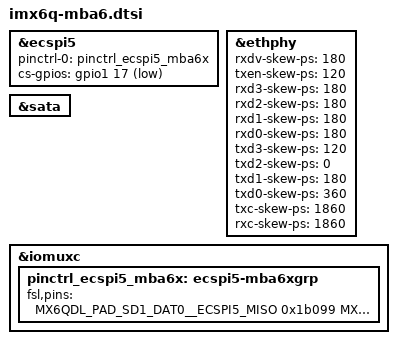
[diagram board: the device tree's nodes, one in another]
// SPDX-License-Identifier: GPL-2.0-only
/*
 * Copyright 2013 Sascha Hauer, Pengutronix
 *
 * Copyright 2013-2021 TQ-Systems GmbH
 * Author: Markus Niebel <Markus.Niebel@tq-group.com>
 */

&ecspi5 {
	pinctrl-names = "default";
	pinctrl-0 = <&pinctrl_ecspi5_mba6x>;
	cs-gpios = <&gpio1 17 GPIO_ACTIVE_LOW>;
};

&ethphy {
	rxdv-skew-ps = <180>;
	txen-skew-ps = <120>;
	rxd3-skew-ps = <180>;
	rxd2-skew-ps = <180>;
	rxd1-skew-ps = <180>;
	rxd0-skew-ps = <180>;
	txd3-skew-ps = <120>;
	txd2-skew-ps = <0>;
	txd1-skew-ps = <180>;
	txd0-skew-ps = <360>;
	txc-skew-ps = <1860>;
	rxc-skew-ps = <1860>;
};

&sata {
	status = "okay";
};

&iomuxc {
	pinctrl_ecspi5_mba6x: ecspi5-mba6xgrp {
		fsl,pins = <
			/* HYS, SPEED = MED, 100k up, DSE = 011, SRE_FAST */
			MX6QDL_PAD_SD1_DAT0__ECSPI5_MISO 0x1b099
			MX6QDL_PAD_SD1_CMD__ECSPI5_MOSI 0xb099
			MX6QDL_PAD_SD1_CLK__ECSPI5_SCLK 0xb099
			MX6QDL_PAD_SD1_DAT1__GPIO1_IO17 0xb099 /* eCSPI5 SS0 */
		>;
	};
};
